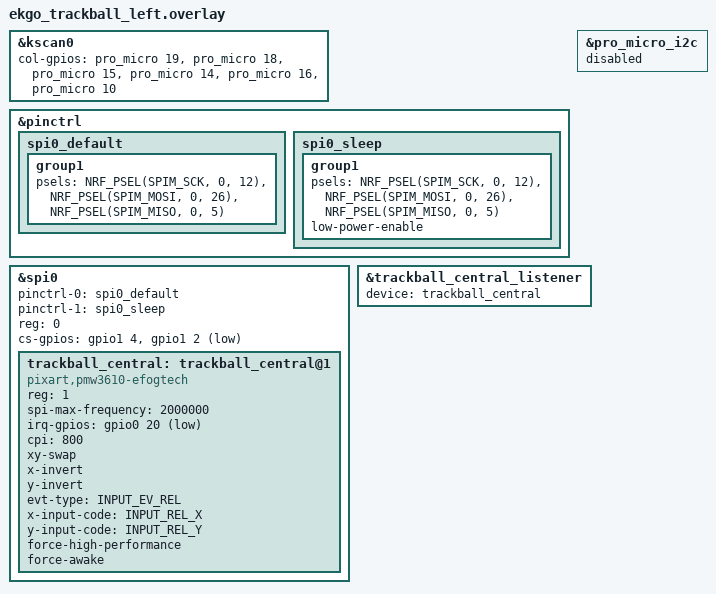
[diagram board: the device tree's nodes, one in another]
/*
 * Copyright (c) 2020 The ZMK Contributors
 *
 * SPDX-License-Identifier: MIT
 */

#include "ekgo_trackball.dtsi"

&kscan0 {
    col-gpios
        = <&pro_micro 19 GPIO_ACTIVE_HIGH>
		, <&pro_micro 18 GPIO_ACTIVE_HIGH>
		, <&pro_micro 15 GPIO_ACTIVE_HIGH>
		, <&pro_micro 14 GPIO_ACTIVE_HIGH>
		, <&pro_micro 16 GPIO_ACTIVE_HIGH>
        , <&pro_micro 10 GPIO_ACTIVE_HIGH>
        ;
};

&pinctrl {
    spi0_default: spi0_default {
        group1 {
            psels = <NRF_PSEL(SPIM_SCK,  0, 12)>,
                    <NRF_PSEL(SPIM_MOSI, 0, 26)>,
                    <NRF_PSEL(SPIM_MISO, 0, 5)>; 
        };
    };
    spi0_sleep: spi0_sleep {
        group1 {
            psels = <NRF_PSEL(SPIM_SCK,  0, 12)>,  
                    <NRF_PSEL(SPIM_MOSI, 0, 26)>,
                    <NRF_PSEL(SPIM_MISO, 0, 5)>; 
            low-power-enable;
        };
    };
};

&pro_micro_i2c {
    status = "disabled";
};

nice_view_spi: &spi0 {
    status = "okay";
    pinctrl-0 = <&spi0_default>;
    pinctrl-1 = <&spi0_sleep>;
    pinctrl-names = "default", "sleep";
    reg = <0>;
    cs-gpios = <&gpio1 4 GPIO_ACTIVE_HIGH>, // nice view
               <&gpio1 2 GPIO_ACTIVE_LOW>; // trackball

    trackball_central: trackball_central@1 {
        status = "okay";
        compatible = "pixart,pmw3610-efogtech";
        reg = <1>;
        spi-max-frequency = <2000000>;
        irq-gpios = <&gpio0 20 (GPIO_ACTIVE_LOW | GPIO_PULL_UP)>;
        cpi = <800>;
        xy-swap;
        x-invert;
        y-invert;
        evt-type = <INPUT_EV_REL>;
        x-input-code = <INPUT_REL_X>;
        y-input-code = <INPUT_REL_Y>;
        force-high-performance;
        force-awake;
        /* keep the sensor awake while ZMK activity state is ACTIVE,
            fallback to normal downshift mode after ZMK goes into IDLE / SLEEP mode.
            thus, the sensor would be a `wakeup-source` */
    };
};

// Overrides for the input listener node
&trackball_central_listener {
    status = "okay";
    device = <&trackball_central>;
    //input-processors = <&zip_ble_report_rate_limit>;
};
